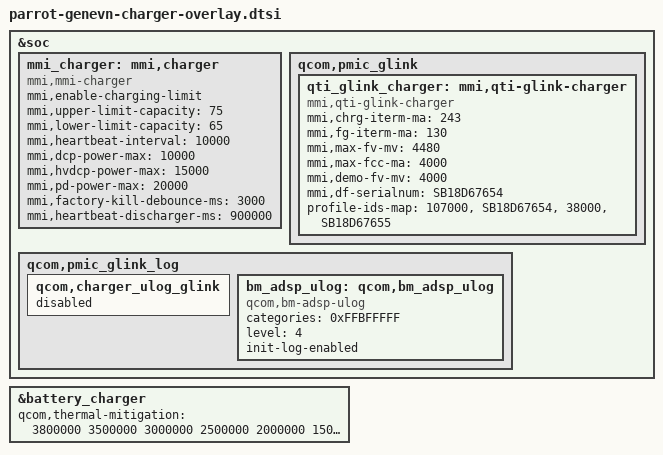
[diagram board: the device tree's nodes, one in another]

&soc {
	mmi_charger: mmi,charger {
		compatible = "mmi,mmi-charger";
		mmi,enable-charging-limit;
		mmi,upper-limit-capacity = <75>;
		mmi,lower-limit-capacity = <65>;
		mmi,heartbeat-interval = <10000>;
		mmi,dcp-power-max = <10000>;
		mmi,hvdcp-power-max = <15000>;
		mmi,pd-power-max = <20000>;
		mmi,factory-kill-debounce-ms = <3000>;
		mmi,heartbeat-discharger-ms = <900000>;
	};

	qcom,pmic_glink {
		status = "ok";
		qti_glink_charger: mmi,qti-glink-charger {
			compatible = "mmi,qti-glink-charger";
			mmi,chrg-iterm-ma = <243>;
			mmi,fg-iterm-ma = <130>;
			mmi,max-fv-mv = <4480>;
			mmi,max-fcc-ma = <4000>;
			mmi,demo-fv-mv = <4000>;
			mmi,df-serialnum = "SB18D67654";
			profile-ids-map = "107000", "SB18D67654","38000","SB18D67655";
		};
	};

	qcom,pmic_glink_log {
		qcom,charger_ulog_glink {
			status = "disabled";
		};
		bm_adsp_ulog: qcom,bm_adsp_ulog {
			compatible = "qcom,bm-adsp-ulog";
			categories = <0xFFBFFFFF>;
			level = <4>;
			init-log-enabled;
		};
	};
};

&battery_charger {
	status = "ok";
	qcom,thermal-mitigation = <3800000 3500000 3000000 2500000 2000000 1500000 1000000 500000 300000>;
};
